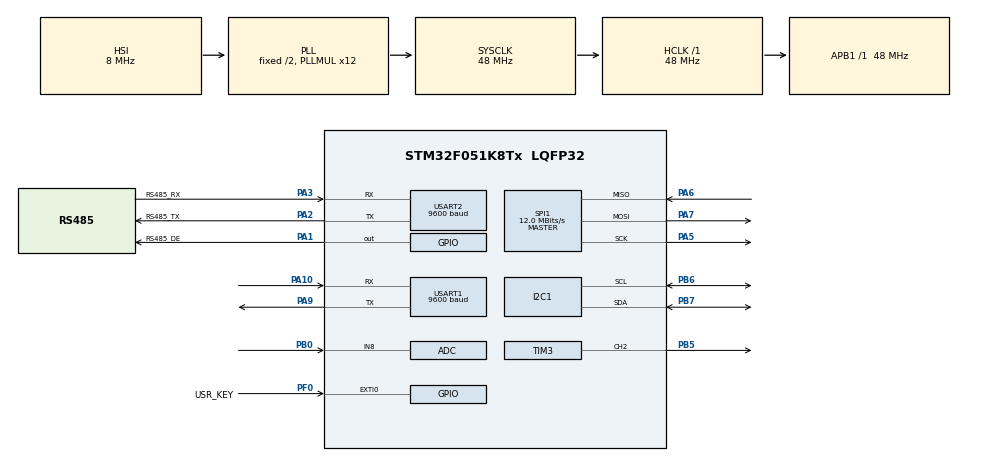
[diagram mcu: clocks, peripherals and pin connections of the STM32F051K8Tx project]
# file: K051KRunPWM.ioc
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Mcu.Family=STM32F0
Mcu.Name=STM32F051K8Tx
Mcu.Package=LQFP32
NVIC.EXTI0_1_IRQn=true\:0\:0\:false\:false\:true\:true\:true
NVIC.USART2_IRQn=true\:0\:0\:false\:false\:true\:true\:true
PA1.GPIO_Label=RS485_DE
PA1.Signal=GPIO_Output
PA10.Mode=Asynchronous
PA10.Signal=USART1_RX
PA13.Mode=Serial_Wire
PA13.Signal=SYS_SWDIO
PA14.Mode=Serial_Wire
PA14.Signal=SYS_SWCLK
PA2.GPIO_Label=RS485_TX
PA2.Mode=Asynchronous
PA2.Signal=USART2_TX
PA3.GPIO_Label=RS485_RX
PA3.Mode=Asynchronous
PA3.Signal=USART2_RX
PA5.Mode=Full_Duplex_Master
PA5.Signal=SPI1_SCK
PA6.Mode=Full_Duplex_Master
PA6.Signal=SPI1_MISO
PA7.Mode=Full_Duplex_Master
PA7.Signal=SPI1_MOSI
PA9.Mode=Asynchronous
PA9.Signal=USART1_TX
PB0.Mode=IN8
PB0.Signal=ADC_IN8
PB5.Signal=S_TIM3_CH2
PB6.Mode=I2C
PB6.Signal=I2C1_SCL
PB7.Mode=I2C
PB7.Signal=I2C1_SDA
PF0-OSC_IN.GPIO_Label=USR_KEY
PF0-OSC_IN.Signal=GPXTI0
ProjectManager.HeapSize=0x200
ProjectManager.StackSize=0x400
ProjectManager.TargetToolchain=STM32CubeIDE
RCC.AHBFreq_Value=48000000
RCC.APB1Freq_Value=48000000
RCC.APB1TimFreq_Value=48000000
RCC.HCLKFreq_Value=48000000
RCC.PLLMUL=RCC_PLL_MUL12
RCC.SYSCLKFreq_VALUE=48000000
RCC.SYSCLKSource=RCC_SYSCLKSOURCE_PLLCLK
SH.S_TIM3_CH2.0=TIM3_CH2,PWM Generation2 CH2
SPI1.BaudRatePrescaler=SPI_BAUDRATEPRESCALER_4
SPI1.CalculateBaudRate=12.0 MBits/s
SPI1.DataSize=SPI_DATASIZE_4BIT
SPI1.Direction=SPI_DIRECTION_2LINES
SPI1.Mode=SPI_MODE_MASTER
SPI1.VirtualType=VM_MASTER
TIM3.Channel-PWM\ Generation2\ CH2=TIM_CHANNEL_2
USART1.BaudRate=9600
USART1.VirtualMode-Asynchronous=VM_ASYNC
USART2.BaudRate=9600
USART2.VirtualMode-Asynchronous=VM_ASYNC
VP_TIM3_VS_ClockSourceINT.Mode=Internal
board=custom

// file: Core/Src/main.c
/* USER CODE BEGIN Header */
/**
  ******************************************************************************
  * @file           : main.c
  * @brief          : Main program body
  ******************************************************************************
  * @attention
  *
  * <h2><center>&copy; Copyright (c) 2022 STMicroelectronics.
  * All rights reserved.</center></h2>
  *
  * This software component is licensed by ST under BSD 3-Clause license,
  * the "License"; You may not use this file except in compliance with the
  * License. You may obtain a copy of the License at:
  *                        opensource.org/licenses/BSD-3-Clause
  *
  ******************************************************************************
  */
/* USER CODE END Header */
#include "main.h"

/* USER CODE BEGIN Includes */
#include "stdio.h"
#include "math.h"
/* USER CODE END Includes */

/* USER CODE BEGIN PTD */
#ifdef __GNUC__
/* With GCC/RAISONANCE, small printf (option LD Linker->Libraries->Small printf
   set to 'Yes') calls __io_putchar() */
#define PUTCHAR_PROTOTYPE int __io_putchar(int ch)
#else
#define PUTCHAR_PROTOTYPE int fputc(int ch, FILE *f)
#endif /* __GNUC__ */

#define TimePeriod 	1000

/* USER CODE END PTD */

ADC_HandleTypeDef hadc;

I2C_HandleTypeDef hi2c1;

SPI_HandleTypeDef hspi1;

TIM_HandleTypeDef htim3;

UART_HandleTypeDef huart1;
UART_HandleTypeDef huart2;

uint32_t x;
uint32_t ADCValue;
float val;
uint16_t PWMValue;

void SystemClock_Config(void);
static void MX_GPIO_Init(void);
static void MX_I2C1_Init(void);
static void MX_SPI1_Init(void);
static void MX_USART1_UART_Init(void);
static void MX_USART2_UART_Init(void);
static void MX_ADC_Init(void);
static void MX_TIM3_Init(void);

int main(void)
{

  /* MCU Configuration--------------------------------------------------------*/

  /* Reset of all peripherals, Initializes the Flash interface and the Systick. */
  HAL_Init();

  /* Configure the system clock */
  SystemClock_Config();

  /* Initialize all configured peripherals */
  MX_GPIO_Init();
  MX_I2C1_Init();
  MX_SPI1_Init();
  MX_USART1_UART_Init();
  MX_USART2_UART_Init();
  MX_ADC_Init();
  MX_TIM3_Init();
  /* USER CODE BEGIN 2 */

  if (HAL_ADCEx_Calibration_Start(&hadc) != HAL_OK)
  {
    printf("ADC initize error\r\n");
    Error_Handler();
  }

  printf("STM32K051 Freq[%ld]\r\n",SystemCoreClock);

  HAL_TIM_PWM_Start(&htim3,TIM_CHANNEL_2);
\
  /* USER CODE END 2 */

  /* Infinite loop */
  while (1)
  {
	  HAL_ADC_Start(&hadc);

	  if(HAL_ADC_PollForConversion(&hadc,100) == HAL_OK)
	  {
		  ADCValue = HAL_ADC_GetValue(&hadc);
	  }
      val = (float)ADCValue/pow(2,12);
      PWMValue = ((2.5*val)/20)*TimePeriod;
	  printf("Count[%ld],Value= [%d] ,VR[%d]\%%,PWM value[%d]\r\n",x,(uint16_t)ADCValue ,(uint8_t)((val) * 100),PWMValue);

	  if(PWMValue < 25)
	  {
		  __HAL_TIM_SET_COMPARE(&htim3,TIM_CHANNEL_2,25);
	  }
	  else
	  {
		  __HAL_TIM_SET_COMPARE(&htim3,TIM_CHANNEL_2,PWMValue);
	  }

	  HAL_Delay(250);
	  x++;
  }
}

/**
  * @brief  Retargets the C library printf function to the USART.
  * @param  None
  * @retval None
  */
PUTCHAR_PROTOTYPE
{
  /* Place your implementation of fputc here */
  /* e.g. write a character to the USART2 and Loop until the end of transmission */
  HAL_UART_Transmit(&huart1, (uint8_t *)&ch, 1, 0xFFFF);
  //ITM_SendChar(ch);
  return ch;
}

void SystemClock_Config(void)
{
  RCC_OscInitTypeDef RCC_OscInitStruct = {0};
  RCC_ClkInitTypeDef RCC_ClkInitStruct = {0};
  RCC_PeriphCLKInitTypeDef PeriphClkInit = {0};

  /** Initializes the RCC Oscillators according to the specified parameters
  * in the RCC_OscInitTypeDef structure.
  */
  RCC_OscInitStruct.OscillatorType = RCC_OSCILLATORTYPE_HSI|RCC_OSCILLATORTYPE_HSI14;
  RCC_OscInitStruct.HSIState = RCC_HSI_ON;
  RCC_OscInitStruct.HSI14State = RCC_HSI14_ON;
  RCC_OscInitStruct.HSICalibrationValue = RCC_HSICALIBRATION_DEFAULT;
  RCC_OscInitStruct.HSI14CalibrationValue = 16;
  RCC_OscInitStruct.PLL.PLLState = RCC_PLL_ON;
  RCC_OscInitStruct.PLL.PLLSource = RCC_PLLSOURCE_HSI;
  RCC_OscInitStruct.PLL.PLLMUL = RCC_PLL_MUL12;
  RCC_OscInitStruct.PLL.PREDIV = RCC_PREDIV_DIV1;
  if (HAL_RCC_OscConfig(&RCC_OscInitStruct) != HAL_OK)
  {
    Error_Handler();
  }
  /** Initializes the CPU, AHB and APB buses clocks
  */
  RCC_ClkInitStruct.ClockType = RCC_CLOCKTYPE_HCLK|RCC_CLOCKTYPE_SYSCLK
                              |RCC_CLOCKTYPE_PCLK1;
  RCC_ClkInitStruct.SYSCLKSource = RCC_SYSCLKSOURCE_PLLCLK;
  RCC_ClkInitStruct.AHBCLKDivider = RCC_SYSCLK_DIV1;
  RCC_ClkInitStruct.APB1CLKDivider = RCC_HCLK_DIV1;

  if (HAL_RCC_ClockConfig(&RCC_ClkInitStruct, FLASH_LATENCY_1) != HAL_OK)
  {
    Error_Handler();
  }
  PeriphClkInit.PeriphClockSelection = RCC_PERIPHCLK_USART1|RCC_PERIPHCLK_I2C1;
  PeriphClkInit.Usart1ClockSelection = RCC_USART1CLKSOURCE_PCLK1;
  PeriphClkInit.I2c1ClockSelection = RCC_I2C1CLKSOURCE_HSI;
  if (HAL_RCCEx_PeriphCLKConfig(&PeriphClkInit) != HAL_OK)
  {
    Error_Handler();
  }
}

static void MX_ADC_Init(void)
{

  ADC_ChannelConfTypeDef sConfig = {0};

  /** Configure the global features of the ADC (Clock, Resolution, Data Alignment and number of conversion)
  */
  hadc.Instance = ADC1;
  hadc.Init.ClockPrescaler = ADC_CLOCK_SYNC_PCLK_DIV4;
  hadc.Init.Resolution = ADC_RESOLUTION_12B;
  hadc.Init.DataAlign = ADC_DATAALIGN_RIGHT;
  hadc.Init.ScanConvMode = ADC_SCAN_DIRECTION_FORWARD;
  hadc.Init.EOCSelection = ADC_EOC_SINGLE_CONV;
  hadc.Init.LowPowerAutoWait = DISABLE;
  hadc.Init.LowPowerAutoPowerOff = DISABLE;
  hadc.Init.ContinuousConvMode = ENABLE;
  hadc.Init.DiscontinuousConvMode = DISABLE;
  hadc.Init.ExternalTrigConv = ADC_SOFTWARE_START;
  hadc.Init.ExternalTrigConvEdge = ADC_EXTERNALTRIGCONVEDGE_NONE;
  hadc.Init.DMAContinuousRequests = DISABLE;
  hadc.Init.Overrun = ADC_OVR_DATA_PRESERVED;
  if (HAL_ADC_Init(&hadc) != HAL_OK)
  {
    Error_Handler();
  }
  /** Configure for the selected ADC regular channel to be converted.
  */
  sConfig.Channel = ADC_CHANNEL_8;
  sConfig.Rank = ADC_RANK_CHANNEL_NUMBER;
  sConfig.SamplingTime = ADC_SAMPLETIME_239CYCLES_5;
  if (HAL_ADC_ConfigChannel(&hadc, &sConfig) != HAL_OK)
  {
    Error_Handler();
  }

}

static void MX_I2C1_Init(void)
{

  hi2c1.Instance = I2C1;
  hi2c1.Init.Timing = 0x2000090E;
  hi2c1.Init.OwnAddress1 = 0;
  hi2c1.Init.AddressingMode = I2C_ADDRESSINGMODE_7BIT;
  hi2c1.Init.DualAddressMode = I2C_DUALADDRESS_DISABLE;
  hi2c1.Init.OwnAddress2 = 0;
  hi2c1.Init.OwnAddress2Masks = I2C_OA2_NOMASK;
  hi2c1.Init.GeneralCallMode = I2C_GENERALCALL_DISABLE;
  hi2c1.Init.NoStretchMode = I2C_NOSTRETCH_DISABLE;
  if (HAL_I2C_Init(&hi2c1) != HAL_OK)
  {
    Error_Handler();
  }
  /** Configure Analogue filter
  */
  if (HAL_I2CEx_ConfigAnalogFilter(&hi2c1, I2C_ANALOGFILTER_ENABLE) != HAL_OK)
  {
    Error_Handler();
  }
  /** Configure Digital filter
  */
  if (HAL_I2CEx_ConfigDigitalFilter(&hi2c1, 0) != HAL_OK)
  {
    Error_Handler();
  }

}

static void MX_SPI1_Init(void)
{

  /* SPI1 parameter configuration*/
  hspi1.Instance = SPI1;
  hspi1.Init.Mode = SPI_MODE_MASTER;
  hspi1.Init.Direction = SPI_DIRECTION_2LINES;
  hspi1.Init.DataSize = SPI_DATASIZE_4BIT;
  hspi1.Init.CLKPolarity = SPI_POLARITY_LOW;
  hspi1.Init.CLKPhase = SPI_PHASE_1EDGE;
  hspi1.Init.NSS = SPI_NSS_SOFT;
  hspi1.Init.BaudRatePrescaler = SPI_BAUDRATEPRESCALER_4;
  hspi1.Init.FirstBit = SPI_FIRSTBIT_MSB;
  hspi1.Init.TIMode = SPI_TIMODE_DISABLE;
  hspi1.Init.CRCCalculation = SPI_CRCCALCULATION_DISABLE;
  hspi1.Init.CRCPolynomial = 7;
  hspi1.Init.CRCLength = SPI_CRC_LENGTH_DATASIZE;
  hspi1.Init.NSSPMode = SPI_NSS_PULSE_ENABLE;
  if (HAL_SPI_Init(&hspi1) != HAL_OK)
  {
    Error_Handler();
  }

}

static void MX_TIM3_Init(void)
{

  TIM_ClockConfigTypeDef sClockSourceConfig = {0};
  TIM_MasterConfigTypeDef sMasterConfig = {0};
  TIM_OC_InitTypeDef sConfigOC = {0};

  htim3.Instance = TIM3;
  htim3.Init.Prescaler = 960 - 1;
  htim3.Init.CounterMode = TIM_COUNTERMODE_UP;
  htim3.Init.Period = TimePeriod - 1;
  htim3.Init.ClockDivision = TIM_CLOCKDIVISION_DIV1;
  htim3.Init.AutoReloadPreload = TIM_AUTORELOAD_PRELOAD_DISABLE;
  if (HAL_TIM_Base_Init(&htim3) != HAL_OK)
  {
    Error_Handler();
  }
  sClockSourceConfig.ClockSource = TIM_CLOCKSOURCE_INTERNAL;
  if (HAL_TIM_ConfigClockSource(&htim3, &sClockSourceConfig) != HAL_OK)
  {
    Error_Handler();
  }
  if (HAL_TIM_PWM_Init(&htim3) != HAL_OK)
  {
    Error_Handler();
  }
  sMasterConfig.MasterOutputTrigger = TIM_TRGO_RESET;
  sMasterConfig.MasterSlaveMode = TIM_MASTERSLAVEMODE_DISABLE;
  if (HAL_TIMEx_MasterConfigSynchronization(&htim3, &sMasterConfig) != HAL_OK)
  {
    Error_Handler();
  }
  sConfigOC.OCMode = TIM_OCMODE_PWM1;
  sConfigOC.Pulse = 0;
  sConfigOC.OCPolarity = TIM_OCPOLARITY_HIGH;
  sConfigOC.OCFastMode = TIM_OCFAST_DISABLE;
  if (HAL_TIM_PWM_ConfigChannel(&htim3, &sConfigOC, TIM_CHANNEL_2) != HAL_OK)
  {
    Error_Handler();
  }
  HAL_TIM_MspPostInit(&htim3);

}

static void MX_USART1_UART_Init(void)
{

  huart1.Instance = USART1;
  huart1.Init.BaudRate = 115200;
  huart1.Init.WordLength = UART_WORDLENGTH_8B;
  huart1.Init.StopBits = UART_STOPBITS_1;
  huart1.Init.Parity = UART_PARITY_NONE;
  huart1.Init.Mode = UART_MODE_TX_RX;
  huart1.Init.HwFlowCtl = UART_HWCONTROL_NONE;
  huart1.Init.OverSampling = UART_OVERSAMPLING_16;
  huart1.Init.OneBitSampling = UART_ONE_BIT_SAMPLE_DISABLE;
  huart1.AdvancedInit.AdvFeatureInit = UART_ADVFEATURE_NO_INIT;
  if (HAL_UART_Init(&huart1) != HAL_OK)
  {
    Error_Handler();
  }

}

static void MX_USART2_UART_Init(void)
{

  huart2.Instance = USART2;
  huart2.Init.BaudRate = 9600;
  huart2.Init.WordLength = UART_WORDLENGTH_8B;
  huart2.Init.StopBits = UART_STOPBITS_1;
  huart2.Init.Parity = UART_PARITY_NONE;
  huart2.Init.Mode = UART_MODE_TX_RX;
  huart2.Init.HwFlowCtl = UART_HWCONTROL_NONE;
  huart2.Init.OverSampling = UART_OVERSAMPLING_16;
  huart2.Init.OneBitSampling = UART_ONE_BIT_SAMPLE_DISABLE;
  huart2.AdvancedInit.AdvFeatureInit = UART_ADVFEATURE_NO_INIT;
  if (HAL_UART_Init(&huart2) != HAL_OK)
  {
    Error_Handler();
  }

}

static void MX_GPIO_Init(void)
{
  GPIO_InitTypeDef GPIO_InitStruct = {0};

  /* GPIO Ports Clock Enable */
  __HAL_RCC_GPIOF_CLK_ENABLE();
  __HAL_RCC_GPIOA_CLK_ENABLE();
  __HAL_RCC_GPIOB_CLK_ENABLE();

  /*Configure GPIO pin Output Level */
  HAL_GPIO_WritePin(RS485_DE_GPIO_Port, RS485_DE_Pin, GPIO_PIN_RESET);

  /*Configure GPIO pin : USR_KEY_Pin */
  GPIO_InitStruct.Pin = USR_KEY_Pin;
  GPIO_InitStruct.Mode = GPIO_MODE_IT_RISING;
  GPIO_InitStruct.Pull = GPIO_NOPULL;
  HAL_GPIO_Init(USR_KEY_GPIO_Port, &GPIO_InitStruct);

  /*Configure GPIO pin : RS485_DE_Pin */
  GPIO_InitStruct.Pin = RS485_DE_Pin;
  GPIO_InitStruct.Mode = GPIO_MODE_OUTPUT_PP;
  GPIO_InitStruct.Pull = GPIO_NOPULL;
  GPIO_InitStruct.Speed = GPIO_SPEED_FREQ_LOW;
  HAL_GPIO_Init(RS485_DE_GPIO_Port, &GPIO_InitStruct);

  /* EXTI interrupt init*/
  HAL_NVIC_SetPriority(EXTI0_1_IRQn, 0, 0);
  HAL_NVIC_EnableIRQ(EXTI0_1_IRQn);

}

void Error_Handler(void)
{
  __disable_irq();
  while (1)
  {
  }
}

/************************ (C) COPYRIGHT STMicroelectronics *****END OF FILE****/
